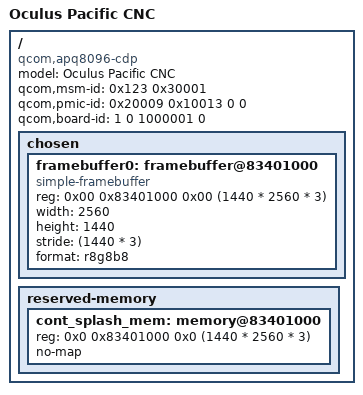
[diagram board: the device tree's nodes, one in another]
// SPDX-License-Identifier: BSD-3-Clause

/dts-v1/;

#include "msm8996.dtsi"
#include "pm8994.dtsi"
#include "pmi8994.dtsi"

/ {
	model = "Oculus Pacific CNC";
	compatible = "qcom,apq8096-cdp", "qcom,apq8096", "qcom,cdp";
	qcom,msm-id = <0x123 0x30001>;
	qcom,pmic-id = <0x20009 0x10013 0 0>;
	qcom,board-id = <1 0 1000001 0>;

	chosen {
		#address-cells = <2>;
		#size-cells = <2>;
		ranges;

		framebuffer0: framebuffer@83401000 {
			compatible = "simple-framebuffer";
			reg = <0x00 0x83401000 0x00 (1440 * 2560 * 3)>;
			width = <2560>;
			height = <1440>;
			stride = <(1440 * 3)>;
			format = "r8g8b8";
		};
	};

	reserved-memory {
		cont_splash_mem: memory@83401000 {
			reg = <0x0 0x83401000 0x0 (1440 * 2560 * 3)>;
			no-map;
		};
	};
};
